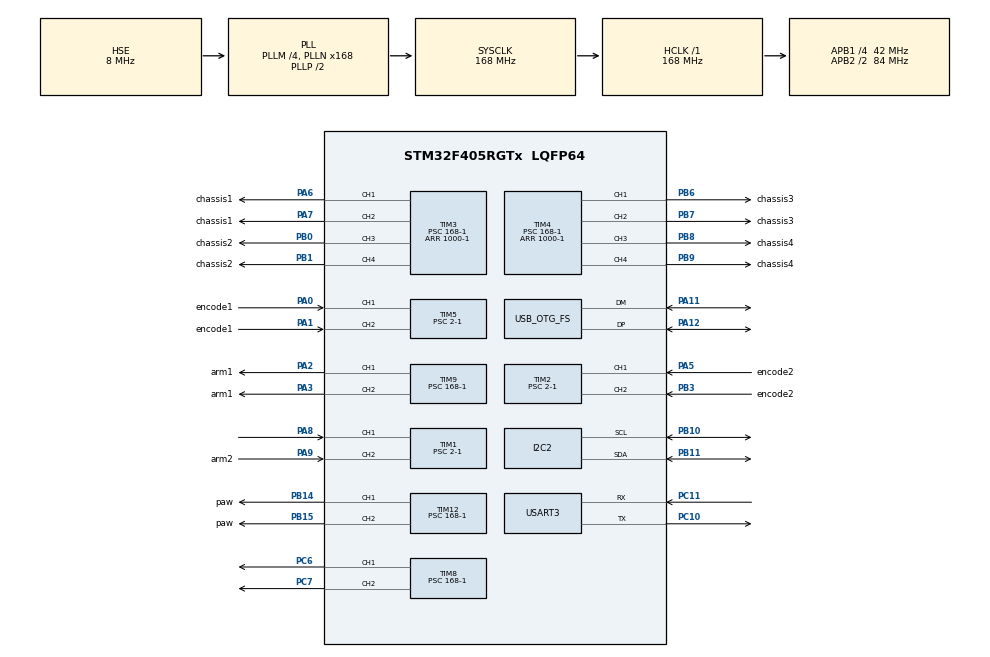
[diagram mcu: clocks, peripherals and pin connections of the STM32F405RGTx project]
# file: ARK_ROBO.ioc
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FREERTOS.Tasks01=defaultTask,0,128,StartDefaultTask,Default,NULL,Dynamic,NULL,NULL;remote_task,0,1024,remotetask,As external,NULL,Dynamic,NULL,NULL;chassis_task,0,512,chassis,As external,NULL,Dynamic,NULL,NULL;arm_task,0,512,arm,As external,NULL,Dynamic,NULL,NULL;oled_task,0,1024,oled,As external,NULL,Dynamic,NULL,NULL
Mcu.Family=STM32F4
Mcu.Name=STM32F405RGTx
Mcu.Package=LQFP64
NVIC.OTG_FS_IRQn=true\:5\:0\:false\:false\:true\:true\:false\:true\:true
NVIC.PriorityGroup=NVIC_PRIORITYGROUP_4
NVIC.TIM6_DAC_IRQn=true\:15\:0\:false\:false\:true\:false\:false\:true\:true
NVIC.TimeBase=TIM6_DAC_IRQn
NVIC.TimeBaseIP=TIM6
NVIC.USART3_IRQn=true\:5\:0\:false\:false\:true\:true\:true\:true\:true
PA0-WKUP.GPIO_Label=encode1
PA0-WKUP.Signal=S_TIM5_CH1
PA1.GPIO_Label=encode1
PA1.Signal=S_TIM5_CH2
PA11.Mode=Device_Only
PA11.Signal=USB_OTG_FS_DM
PA12.Mode=Device_Only
PA12.Signal=USB_OTG_FS_DP
PA13.Mode=Serial_Wire
PA13.Signal=SYS_JTMS-SWDIO
PA14.Mode=Serial_Wire
PA14.Signal=SYS_JTCK-SWCLK
PA2.GPIO_Label=arm1
PA2.Signal=S_TIM9_CH1
PA3.GPIO_Label=arm1
PA3.Signal=S_TIM9_CH2
PA5.GPIO_Label=encode2
PA5.Signal=S_TIM2_CH1_ETR
PA6.GPIO_Label=chassis1
PA6.Signal=S_TIM3_CH1
PA7.GPIO_Label=chassis1
PA7.Signal=S_TIM3_CH2
PA8.Signal=S_TIM1_CH1
PA9.GPIO_Label=arm2
PA9.Signal=S_TIM1_CH2
PB0.GPIO_Label=chassis2
PB0.Signal=S_TIM3_CH3
PB1.GPIO_Label=chassis2
PB1.Signal=S_TIM3_CH4
PB10.GPIO_Pu=GPIO_NOPULL
PB10.Mode=I2C
PB10.Signal=I2C2_SCL
PB11.GPIO_Pu=GPIO_NOPULL
PB11.GPIO_Speed=GPIO_SPEED_FREQ_VERY_HIGH
PB11.Mode=I2C
PB11.Signal=I2C2_SDA
PB14.GPIO_Label=paw
PB14.Signal=S_TIM12_CH1
PB15.GPIO_Label=paw
PB15.Signal=S_TIM12_CH2
PB3.GPIO_Label=encode2
PB3.Signal=S_TIM2_CH2
PB6.GPIO_Label=chassis3
PB6.Signal=S_TIM4_CH1
PB7.GPIO_Label=chassis3
PB7.Signal=S_TIM4_CH2
PB8.GPIO_Label=chassis4
PB8.Signal=S_TIM4_CH3
PB9.GPIO_Label=chassis4
PB9.Signal=S_TIM4_CH4
PC10.Mode=Asynchronous
PC10.Signal=USART3_TX
PC11.Mode=Asynchronous
PC11.Signal=USART3_RX
PC6.Signal=S_TIM8_CH1
PC7.Signal=S_TIM8_CH2
PH0-OSC_IN.Mode=HSE-External-Oscillator
PH0-OSC_IN.Signal=RCC_OSC_IN
PH1-OSC_OUT.Mode=HSE-External-Oscillator
PH1-OSC_OUT.Signal=RCC_OSC_OUT
ProjectManager.HeapSize=0x200
ProjectManager.StackSize=0x400
ProjectManager.TargetToolchain=CMake
RCC.48MHZClocksFreq_Value=48000000
RCC.AHBFreq_Value=168000000
RCC.APB1CLKDivider=RCC_HCLK_DIV4
RCC.APB1Freq_Value=42000000
RCC.APB1TimFreq_Value=84000000
RCC.APB2CLKDivider=RCC_HCLK_DIV2
RCC.APB2Freq_Value=84000000
RCC.APB2TimFreq_Value=168000000
RCC.CortexFreq_Value=168000000
RCC.HCLKFreq_Value=168000000
RCC.HSE_VALUE=8000000
RCC.HSI_VALUE=16000000
RCC.LSE_VALUE=32768
RCC.PLLM=4
RCC.PLLN=168
RCC.PLLQ=7
RCC.SYSCLKFreq_VALUE=168000000
RCC.SYSCLKSource=RCC_SYSCLKSOURCE_PLLCLK
RCC.VCOOutputFreq_Value=336000000
SH.S_TIM12_CH1.0=TIM12_CH1,PWM Generation1 CH1
SH.S_TIM12_CH2.0=TIM12_CH2,PWM Generation2 CH2
SH.S_TIM1_CH1.0=TIM1_CH1,Encoder_Interface
SH.S_TIM1_CH2.0=TIM1_CH2,Encoder_Interface
SH.S_TIM2_CH1_ETR.0=TIM2_CH1,Encoder_Interface
SH.S_TIM2_CH2.0=TIM2_CH2,Encoder_Interface
SH.S_TIM3_CH1.0=TIM3_CH1,PWM Generation1 CH1
SH.S_TIM3_CH2.0=TIM3_CH2,PWM Generation2 CH2
SH.S_TIM3_CH3.0=TIM3_CH3,PWM Generation3 CH3
SH.S_TIM3_CH4.0=TIM3_CH4,PWM Generation4 CH4
SH.S_TIM4_CH1.0=TIM4_CH1,PWM Generation1 CH1
SH.S_TIM4_CH2.0=TIM4_CH2,PWM Generation2 CH2
SH.S_TIM4_CH3.0=TIM4_CH3,PWM Generation3 CH3
SH.S_TIM4_CH4.0=TIM4_CH4,PWM Generation4 CH4
SH.S_TIM5_CH1.0=TIM5_CH1,Encoder_Interface
SH.S_TIM5_CH2.0=TIM5_CH2,Encoder_Interface
SH.S_TIM8_CH1.0=TIM8_CH1,PWM Generation1 CH1
SH.S_TIM8_CH2.0=TIM8_CH2,PWM Generation2 CH2
SH.S_TIM9_CH1.0=TIM9_CH1,PWM Generation1 CH1
SH.S_TIM9_CH2.0=TIM9_CH2,PWM Generation2 CH2
TIM1.EncoderMode=TIM_ENCODERMODE_TI1
TIM1.IC1Filter=15
TIM1.IC2Filter=15
TIM1.Prescaler=2-1
TIM12.Channel-PWM\ Generation1\ CH1=TIM_CHANNEL_1
TIM12.Channel-PWM\ Generation2\ CH2=TIM_CHANNEL_2
TIM12.Period=1000-1
TIM12.Prescaler=168-1
TIM2.IC1Filter=15
TIM2.IC2Filter=15
TIM2.Period=65535
TIM2.Prescaler=2-1
TIM3.Channel-PWM\ Generation1\ CH1=TIM_CHANNEL_1
TIM3.Channel-PWM\ Generation2\ CH2=TIM_CHANNEL_2
TIM3.Channel-PWM\ Generation3\ CH3=TIM_CHANNEL_3
TIM3.Channel-PWM\ Generation4\ CH4=TIM_CHANNEL_4
TIM3.Period=1000-1
TIM3.Prescaler=168-1
TIM4.Channel-PWM\ Generation1\ CH1=TIM_CHANNEL_1
TIM4.Channel-PWM\ Generation2\ CH2=TIM_CHANNEL_2
TIM4.Channel-PWM\ Generation3\ CH3=TIM_CHANNEL_3
TIM4.Channel-PWM\ Generation4\ CH4=TIM_CHANNEL_4
TIM4.Period=1000-1
TIM4.Prescaler=168-1
TIM5.EncoderMode=TIM_ENCODERMODE_TI1
TIM5.IC1Filter=15
TIM5.IC2Filter=15
TIM5.Period=65535
TIM5.Prescaler=2-1
TIM8.Channel-PWM\ Generation1\ CH1=TIM_CHANNEL_1
TIM8.Channel-PWM\ Generation2\ CH2=TIM_CHANNEL_2
TIM8.Period=1000-1
TIM8.Prescaler=168-1
TIM9.Channel-PWM\ Generation1\ CH1=TIM_CHANNEL_1
TIM9.Channel-PWM\ Generation2\ CH2=TIM_CHANNEL_2
TIM9.Period=1000-1
TIM9.Prescaler=168-1
USART3.VirtualMode=VM_ASYNC
USB_DEVICE.CLASS_NAME_FS=CDC
USB_DEVICE.VirtualMode-CDC_FS=Cdc
USB_DEVICE.VirtualModeFS=Cdc_FS
USB_OTG_FS.VirtualMode=Device_Only
VP_FREERTOS_VS_CMSIS_V1.Mode=CMSIS_V1
VP_SYS_VS_tim6.Mode=TIM6
VP_TIM12_VS_ClockSourceINT.Mode=Internal
VP_TIM3_VS_ClockSourceINT.Mode=Internal
VP_TIM4_VS_ClockSourceINT.Mode=Internal
VP_TIM8_VS_ClockSourceINT.Mode=Internal
VP_TIM9_VS_ClockSourceINT.Mode=Internal
VP_USB_DEVICE_VS_USB_DEVICE_CDC_FS.Mode=CDC_FS
board=custom

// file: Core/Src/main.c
/* USER CODE BEGIN Header */
/**
  ******************************************************************************
  * @file           : main.c
  * @brief          : Main program body
  ******************************************************************************
  * @attention
  *
  * Copyright (c) 2025 STMicroelectronics.
  * All rights reserved.
  *
  * This software is licensed under terms that can be found in the LICENSE file
  * in the root directory of this software component.
  * If no LICENSE file comes with this software, it is provided AS-IS.
  *
  ******************************************************************************
  */
/* USER CODE END Header */
#include "main.h"
#include "cmsis_os.h"
#include "i2c.h"
#include "tim.h"
#include "usart.h"
#include "usb_device.h"
#include "gpio.h"

/* USER CODE BEGIN PTD */
extern void init();
extern void loop();
/* USER CODE END PTD */

void SystemClock_Config(void);
void MX_FREERTOS_Init(void);

int main(void)
{

  /* MCU Configuration--------------------------------------------------------*/

  /* Reset of all peripherals, Initializes the Flash interface and the Systick. */
  HAL_Init();

  /* Configure the system clock */
  SystemClock_Config();

  /* Initialize all configured peripherals */
  MX_GPIO_Init();
  MX_I2C2_Init();
  MX_TIM1_Init();
  MX_TIM2_Init();
  MX_TIM3_Init();
  MX_TIM4_Init();
  MX_TIM5_Init();
  MX_TIM8_Init();
  MX_TIM9_Init();
  MX_TIM12_Init();
  MX_USART3_UART_Init();
  /* USER CODE BEGIN 2 */
  HAL_Delay(500);
  /* USER CODE END 2 */

  /* Call init function for freertos objects (in cmsis_os2.c) */
  MX_FREERTOS_Init();

  /* Start scheduler */
  osKernelStart();

  /* We should never get here as control is now taken by the scheduler */

  /* Infinite loop */
  while (1)
  {

  }
}

void SystemClock_Config(void)
{
  RCC_OscInitTypeDef RCC_OscInitStruct = {0};
  RCC_ClkInitTypeDef RCC_ClkInitStruct = {0};

  /** Configure the main internal regulator output voltage
  */
  __HAL_RCC_PWR_CLK_ENABLE();
  __HAL_PWR_VOLTAGESCALING_CONFIG(PWR_REGULATOR_VOLTAGE_SCALE1);

  /** Initializes the RCC Oscillators according to the specified parameters
  * in the RCC_OscInitTypeDef structure.
  */
  RCC_OscInitStruct.OscillatorType = RCC_OSCILLATORTYPE_HSE;
  RCC_OscInitStruct.HSEState = RCC_HSE_ON;
  RCC_OscInitStruct.PLL.PLLState = RCC_PLL_ON;
  RCC_OscInitStruct.PLL.PLLSource = RCC_PLLSOURCE_HSE;
  RCC_OscInitStruct.PLL.PLLM = 4;
  RCC_OscInitStruct.PLL.PLLN = 168;
  RCC_OscInitStruct.PLL.PLLP = RCC_PLLP_DIV2;
  RCC_OscInitStruct.PLL.PLLQ = 7;
  if (HAL_RCC_OscConfig(&RCC_OscInitStruct) != HAL_OK)
  {
    Error_Handler();
  }

  /** Initializes the CPU, AHB and APB buses clocks
  */
  RCC_ClkInitStruct.ClockType = RCC_CLOCKTYPE_HCLK|RCC_CLOCKTYPE_SYSCLK
                              |RCC_CLOCKTYPE_PCLK1|RCC_CLOCKTYPE_PCLK2;
  RCC_ClkInitStruct.SYSCLKSource = RCC_SYSCLKSOURCE_PLLCLK;
  RCC_ClkInitStruct.AHBCLKDivider = RCC_SYSCLK_DIV1;
  RCC_ClkInitStruct.APB1CLKDivider = RCC_HCLK_DIV4;
  RCC_ClkInitStruct.APB2CLKDivider = RCC_HCLK_DIV2;

  if (HAL_RCC_ClockConfig(&RCC_ClkInitStruct, FLASH_LATENCY_5) != HAL_OK)
  {
    Error_Handler();
  }
}

void HAL_TIM_PeriodElapsedCallback(TIM_HandleTypeDef *htim)
{
  if (htim->Instance == TIM6) {
    HAL_IncTick();
  }
}

void Error_Handler(void)
{
  __disable_irq();
  while (1)
  {
  }
}

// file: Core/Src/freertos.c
/* USER CODE BEGIN Header */
/**
  ******************************************************************************
  * File Name          : freertos.c
  * Description        : Code for freertos applications
  ******************************************************************************
  * @attention
  *
  * Copyright (c) 2025 STMicroelectronics.
  * All rights reserved.
  *
  * This software is licensed under terms that can be found in the LICENSE file
  * in the root directory of this software component.
  * If no LICENSE file comes with this software, it is provided AS-IS.
  *
  ******************************************************************************
  */
/* USER CODE END Header */

#include "FreeRTOS.h"
#include "task.h"
#include "main.h"
#include "cmsis_os.h"

/* USER CODE BEGIN Includes */
#include "tim.h"
/* USER CODE END Includes */

osThreadId defaultTaskHandle;
osThreadId remote_taskHandle;
osThreadId chassis_taskHandle;
osThreadId arm_taskHandle;
osThreadId oled_taskHandle;

void StartDefaultTask(void const * argument);
extern void remotetask(void const * argument);
extern void chassis(void const * argument);
extern void arm(void const * argument);
extern void oled(void const * argument);

extern void MX_USB_DEVICE_Init(void);
void MX_FREERTOS_Init(void); /* (MISRA C 2004 rule 8.1) */

/* GetIdleTaskMemory prototype (linked to static allocation support) */
void vApplicationGetIdleTaskMemory( StaticTask_t **ppxIdleTaskTCBBuffer, StackType_t **ppxIdleTaskStackBuffer, uint32_t *pulIdleTaskStackSize );

/* USER CODE BEGIN GET_IDLE_TASK_MEMORY */
static StaticTask_t xIdleTaskTCBBuffer;
static StackType_t xIdleStack[configMINIMAL_STACK_SIZE];

void vApplicationGetIdleTaskMemory( StaticTask_t **ppxIdleTaskTCBBuffer, StackType_t **ppxIdleTaskStackBuffer, uint32_t *pulIdleTaskStackSize )
{
  *ppxIdleTaskTCBBuffer = &xIdleTaskTCBBuffer;
  *ppxIdleTaskStackBuffer = &xIdleStack[0];
  *pulIdleTaskStackSize = configMINIMAL_STACK_SIZE;
  /* place for user code */
}
/* USER CODE END GET_IDLE_TASK_MEMORY */

void MX_FREERTOS_Init(void) {

  /* Create the thread(s) */
  /* definition and creation of defaultTask */
  osThreadDef(defaultTask, StartDefaultTask, osPriorityNormal, 0, 128);
  defaultTaskHandle = osThreadCreate(osThread(defaultTask), NULL);

  /* definition and creation of remote_task */
  osThreadDef(remote_task, remotetask, osPriorityNormal, 0, 1024);
  remote_taskHandle = osThreadCreate(osThread(remote_task), NULL);

  /* definition and creation of chassis_task */
  osThreadDef(chassis_task, chassis, osPriorityNormal, 0, 512);
  chassis_taskHandle = osThreadCreate(osThread(chassis_task), NULL);

  /* definition and creation of arm_task */
  osThreadDef(arm_task, arm, osPriorityNormal, 0, 512);
  arm_taskHandle = osThreadCreate(osThread(arm_task), NULL);

  /* definition and creation of oled_task */
  osThreadDef(oled_task, oled, osPriorityNormal, 0, 1024);
  oled_taskHandle = osThreadCreate(osThread(oled_task), NULL);

}

void StartDefaultTask(void const * argument)
{
  /* init code for USB_DEVICE */
  MX_USB_DEVICE_Init();
  for(;;)
  {
    osDelay(1);
  }
}
